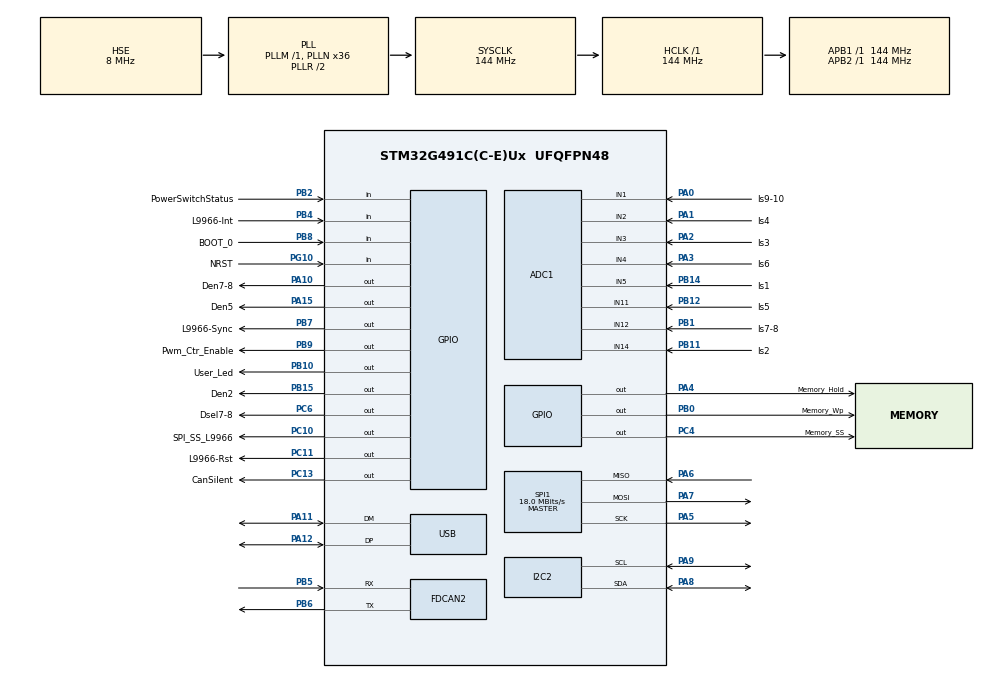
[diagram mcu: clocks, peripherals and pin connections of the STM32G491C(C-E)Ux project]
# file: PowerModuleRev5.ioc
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ADC1.Channel-1\#ChannelRegularConversion=ADC_CHANNEL_5
ADC1.ClockPrescaler=ADC_CLOCK_ASYNC_DIV8
ADC1.DiscontinuousConvMode=DISABLE
ADC1.NbrOfConversion=1
ADC1.NbrOfConversionFlag=1
ADC1.OffsetNumber-1\#ChannelRegularConversion=ADC_OFFSET_NONE
ADC1.Rank-1\#ChannelRegularConversion=1
ADC1.SamplingTime-1\#ChannelRegularConversion=ADC_SAMPLETIME_640CYCLES_5
ADC1.master=1
FDCAN2.CalculateBaudRateNominal=500000
FDCAN2.CalculateTimeBitNominal=2000
FDCAN2.CalculateTimeQuantumNominal=125.0
FDCAN2.DataPrescaler=6
FDCAN2.DataTimeSeg1=13
FDCAN2.DataTimeSeg2=2
FDCAN2.NominalPrescaler=6
FDCAN2.NominalTimeSeg1=13
I2C2.Timing=0x20B0D9FF
Mcu.Family=STM32G4
Mcu.Name=STM32G491C(C-E)Ux
Mcu.Package=UFQFPN48
NVIC.FDCAN2_IT0_IRQn=true\:0\:0\:false\:false\:true\:true\:true\:true
NVIC.PriorityGroup=NVIC_PRIORITYGROUP_4
NVIC.USB_LP_IRQn=true\:0\:0\:false\:false\:true\:false\:true\:true
PA0.GPIO_Label=Is9-10
PA0.GPIO_Mode=GPIO_MODE_ANALOG
PA0.GPIO_PuPd=GPIO_NOPULL
PA0.Mode=IN1-Single-Ended
PA0.Signal=ADC1_IN1
PA1.GPIO_Label=Is4
PA1.GPIO_Mode=GPIO_MODE_ANALOG
PA1.GPIO_PuPd=GPIO_NOPULL
PA1.Mode=IN2-Single-Ended
PA1.Signal=ADC1_IN2
PA10.GPIO_Label=Den7-8
PA10.Signal=GPIO_Output
PA11.Mode=Device
PA11.Signal=USB_DM
PA12.Mode=Device
PA12.Signal=USB_DP
PA13.Mode=Serial_Wire
PA13.Signal=SYS_JTMS-SWDIO
PA14.Mode=Serial_Wire
PA14.Signal=SYS_JTCK-SWCLK
PA15.GPIO_Label=Den5
PA15.Signal=GPIO_Output
PA2.GPIO_Label=Is3
PA2.GPIO_Mode=GPIO_MODE_ANALOG
PA2.GPIO_PuPd=GPIO_NOPULL
PA2.Mode=IN3-Single-Ended
PA2.Signal=ADC1_IN3
PA3.GPIO_Label=Is6
PA3.GPIO_Mode=GPIO_MODE_ANALOG
PA3.GPIO_PuPd=GPIO_NOPULL
PA3.Mode=IN4-Single-Ended
PA3.Signal=ADC1_IN4
PA4.GPIO_Label=Memory_Hold
PA4.PinState=GPIO_PIN_SET
PA4.Signal=GPIO_Output
PA5.Mode=Full_Duplex_Master
PA5.Signal=SPI1_SCK
PA6.Mode=Full_Duplex_Master
PA6.Signal=SPI1_MISO
PA7.Mode=Full_Duplex_Master
PA7.Signal=SPI1_MOSI
PA8.Mode=I2C
PA8.Signal=I2C2_SDA
PA9.Mode=I2C
PA9.Signal=I2C2_SCL
PB0.GPIO_Label=Memory_Wp
PB0.PinState=GPIO_PIN_SET
PB0.Signal=GPIO_Output
PB1.GPIO_Label=Is7-8
PB1.GPIO_Mode=GPIO_MODE_ANALOG
PB1.GPIO_PuPd=GPIO_NOPULL
PB1.Mode=IN12-Single-Ended
PB1.Signal=ADC1_IN12
PB10.GPIO_Label=User_Led
PB10.Signal=GPIO_Output
PB11.GPIO_Label=Is2
PB11.GPIO_Mode=GPIO_MODE_ANALOG
PB11.GPIO_PuPd=GPIO_NOPULL
PB11.Mode=IN14-Single-Ended
PB11.Signal=ADC1_IN14
PB12.GPIO_Label=Is5
PB12.GPIO_Mode=GPIO_MODE_ANALOG
PB12.GPIO_PuPd=GPIO_NOPULL
PB12.Mode=IN11-Single-Ended
PB12.Signal=ADC1_IN11
PB14.GPIO_Label=Is1
PB14.GPIO_Mode=GPIO_MODE_ANALOG
PB14.GPIO_PuPd=GPIO_NOPULL
PB14.Mode=IN5-Single-Ended
PB14.Signal=ADC1_IN5
PB15.GPIO_Label=Den2
PB15.Signal=GPIO_Output
PB2.GPIO_Label=PowerSwitchStatus
PB2.Signal=GPIO_Input
PB3.Signal=SYS_JTDO-SWO
PB4.GPIO_Label=L9966-Int
PB4.Signal=GPIO_Input
PB5.Mode=FDCAN_Activate
PB5.Signal=FDCAN2_RX
PB6.Mode=FDCAN_Activate
PB6.Signal=FDCAN2_TX
PB7.GPIO_Label=L9966-Sync
PB7.Signal=GPIO_Output
PB8-BOOT0.GPIO_Label=BOOT_0
PB8-BOOT0.Signal=GPIO_Input
PB9.GPIO_Label=Pwm_Ctr_Enable
PB9.Signal=GPIO_Output
PC10.GPIO_Label=SPI_SS_L9966
PC10.PinState=GPIO_PIN_SET
PC10.Signal=GPIO_Output
PC11.GPIO_Label=L9966-Rst
PC11.Signal=GPIO_Output
PC13.GPIO_Label=CanSilent
PC13.Signal=GPIO_Output
PC14-OSC32_IN.Mode=LSE-External-Oscillator
PC14-OSC32_IN.Signal=RCC_OSC32_IN
PC15-OSC32_OUT.Mode=LSE-External-Oscillator
PC15-OSC32_OUT.Signal=RCC_OSC32_OUT
PC4.GPIO_Label=Memory_SS
PC4.PinState=GPIO_PIN_SET
PC4.Signal=GPIO_Output
PC6.GPIO_Label=Dsel7-8
PC6.Signal=GPIO_Output
PF0-OSC_IN.Mode=HSE-External-Oscillator
PF0-OSC_IN.Signal=RCC_OSC_IN
PF1-OSC_OUT.Mode=HSE-External-Oscillator
PF1-OSC_OUT.Signal=RCC_OSC_OUT
PG10-NRST.GPIO_Label=NRST
PG10-NRST.Signal=GPIO_Input
ProjectManager.HeapSize=0x200
ProjectManager.StackSize=0x400
ProjectManager.TargetToolchain=Makefile
RCC.ADC12Freq_Value=144000000
RCC.ADC345Freq_Value=144000000
RCC.AHBFreq_Value=144000000
RCC.APB1Freq_Value=144000000
RCC.APB1TimFreq_Value=144000000
RCC.APB2Freq_Value=144000000
RCC.APB2TimFreq_Value=144000000
RCC.CK48CLockSelection=RCC_USBCLKSOURCE_PLL
RCC.CortexFreq_Value=144000000
RCC.EXTERNAL_CLOCK_VALUE=12288000
RCC.FDCANCLockSelection=RCC_FDCANCLKSOURCE_PLL
RCC.HCLKFreq_Value=144000000
RCC.HSE_VALUE=8000000
RCC.HSI48_VALUE=48000000
RCC.HSI_VALUE=16000000
RCC.PLLN=36
RCC.PLLP=RCC_PLLP_DIV30
RCC.PLLQ=RCC_PLLQ_DIV6
RCC.PLLSourceVirtual=RCC_PLLSOURCE_HSE
RCC.SYSCLKFreq_VALUE=144000000
RCC.SYSCLKSource=RCC_SYSCLKSOURCE_PLLCLK
RCC.USBFreq_Value=48000000
RCC.VCOOutputFreq_Value=288000000
SPI1.BaudRatePrescaler=SPI_BAUDRATEPRESCALER_8
SPI1.CalculateBaudRate=18.0 MBits/s
SPI1.Direction=SPI_DIRECTION_2LINES
SPI1.Mode=SPI_MODE_MASTER
SPI1.NSSPMode=SPI_NSS_PULSE_DISABLE
SPI1.VirtualType=VM_MASTER
USB_DEVICE.CLASS_NAME_FS=CDC
USB_DEVICE.VirtualMode=Cdc
USB_DEVICE.VirtualModeFS=Cdc_FS
VP_SYS_VS_DBSignals.Mode=DisableDeadBatterySignals
VP_USB_DEVICE_VS_USB_DEVICE_CDC_FS.Mode=CDC_FS
board=custom

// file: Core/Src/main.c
/* USER CODE BEGIN Header */
/**
  ******************************************************************************
  * @file           : main.c
  * @brief          : Main program body
  ******************************************************************************
  * @attention
  *
  * Copyright (c) 2023 STMicroelectronics.
  * All rights reserved.
  *
  * This software is licensed under terms that can be found in the LICENSE file
  * in the root directory of this software component.
  * If no LICENSE file comes with this software, it is provided AS-IS.
  *
  ******************************************************************************
  */
/* USER CODE END Header */
#include "main.h"
#include "adc.h"
#include "fdcan.h"
#include "i2c.h"
#include "spi.h"
#include "usb_device.h"
#include "gpio.h"

/* USER CODE BEGIN Includes */
#include "BootloaderTools.h"
#include "cppMain.h"
/* USER CODE END Includes */

void SystemClock_Config(void);

int main(void)
{
  /* USER CODE BEGIN 1 */

  checkAndGoToBootloader();

  /* USER CODE END 1 */

  /* MCU Configuration--------------------------------------------------------*/

  /* Reset of all peripherals, Initializes the Flash interface and the Systick. */
  HAL_Init();

  /* Configure the system clock */
  SystemClock_Config();

  /* Initialize all configured peripherals */
  MX_GPIO_Init();
  MX_ADC1_Init();
  MX_SPI1_Init();
  MX_FDCAN2_Init();
  MX_I2C2_Init();
  MX_USB_Device_Init();
  /* USER CODE BEGIN 2 */
  cppMain();
  /* USER CODE END 2 */

  /* Infinite loop */
  while (1)
  {

  }
}

void SystemClock_Config(void)
{
  RCC_OscInitTypeDef RCC_OscInitStruct = {0};
  RCC_ClkInitTypeDef RCC_ClkInitStruct = {0};

  /** Configure the main internal regulator output voltage
  */
  HAL_PWREx_ControlVoltageScaling(PWR_REGULATOR_VOLTAGE_SCALE1);

  /** Initializes the RCC Oscillators according to the specified parameters
  * in the RCC_OscInitTypeDef structure.
  */
  RCC_OscInitStruct.OscillatorType = RCC_OSCILLATORTYPE_HSE;
  RCC_OscInitStruct.HSEState = RCC_HSE_ON;
  RCC_OscInitStruct.PLL.PLLState = RCC_PLL_ON;
  RCC_OscInitStruct.PLL.PLLSource = RCC_PLLSOURCE_HSE;
  RCC_OscInitStruct.PLL.PLLM = RCC_PLLM_DIV1;
  RCC_OscInitStruct.PLL.PLLN = 36;
  RCC_OscInitStruct.PLL.PLLP = RCC_PLLP_DIV30;
  RCC_OscInitStruct.PLL.PLLQ = RCC_PLLQ_DIV6;
  RCC_OscInitStruct.PLL.PLLR = RCC_PLLR_DIV2;
  if (HAL_RCC_OscConfig(&RCC_OscInitStruct) != HAL_OK)
  {
    Error_Handler();
  }

  /** Initializes the CPU, AHB and APB buses clocks
  */
  RCC_ClkInitStruct.ClockType = RCC_CLOCKTYPE_HCLK|RCC_CLOCKTYPE_SYSCLK
                              |RCC_CLOCKTYPE_PCLK1|RCC_CLOCKTYPE_PCLK2;
  RCC_ClkInitStruct.SYSCLKSource = RCC_SYSCLKSOURCE_PLLCLK;
  RCC_ClkInitStruct.AHBCLKDivider = RCC_SYSCLK_DIV1;
  RCC_ClkInitStruct.APB1CLKDivider = RCC_HCLK_DIV1;
  RCC_ClkInitStruct.APB2CLKDivider = RCC_HCLK_DIV1;

  if (HAL_RCC_ClockConfig(&RCC_ClkInitStruct, FLASH_LATENCY_4) != HAL_OK)
  {
    Error_Handler();
  }
}

void Error_Handler(void)
{
  __disable_irq();
  while (1)
  {
  }
}
